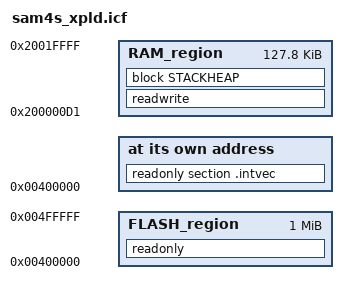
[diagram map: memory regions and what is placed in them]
/* [FLASH] */
define symbol __region_FLASH_start__    = 0x00400000 ;
define symbol __region_FLASH_size__     = 0x00100000 ;
define symbol __region_FLASH_end__      = __region_FLASH_start__+__region_FLASH_size__-1 ;
define symbol __intvec_start__          = __region_FLASH_start__ ;

/* [RAM] Vector table dynamic copy: 16+35 vectors * 4 bytes = 204 bytes (0xcc) */
define symbol __NVIC_core_vectors__     = 16 ;
define symbol __NVIC_device_vectors__   = 35 ;
define symbol __NVIC_vectors_length__   = (__NVIC_core_vectors__+__NVIC_device_vectors__)*4 ;

define symbol __NVIC_start__            = 0x20000000 ;
define symbol __NVIC_end__              = __NVIC_start__+(((__NVIC_vectors_length__+8)/8)*8) ; /* we align RAM start on 8 bytes by padding */
define symbol __region_RAM_start__      = __NVIC_end__+1 ;
define symbol __region_RAM_size__       = 0x00020000 ;
define symbol __region_RAM_end__        = __NVIC_start__+__region_RAM_size__-1 ;

/* Memory regions */
define memory mem with size = 4G;
define region FLASH_region    = mem:[from __region_FLASH_start__ to __region_FLASH_end__];
define region RAM_region      = mem:[from __region_RAM_start__ to __region_RAM_end__];

/* Stack and Heap */
define symbol __size_cstack__ = 0x400;
define symbol __size_heap__   = 0x200;
define block CSTACK    with alignment = 8, size = __size_cstack__ { };
define block HEAP      with alignment = 8, size = __size_heap__ { };
define block STACKHEAP with fixed order { block HEAP, block CSTACK };

initialize by copy with packing = zeros { readwrite };
do not initialize  { section .noinit };

place at address mem:__intvec_start__ { readonly section .intvec };

place in FLASH_region { readonly };
place in RAM_region   { readwrite, block STACKHEAP };
